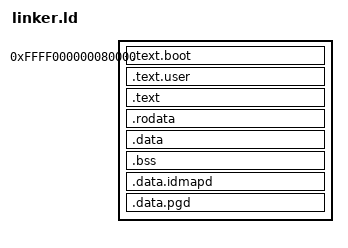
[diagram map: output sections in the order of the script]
SECTIONS
{
	. = 0xffff000000080000;
	.text.boot : { *(.text.boot) }
	. = ALIGN(0x00001000);
	user_begin = .;
	.text.user : { *(.text.user) }
	user_end = .;
	.text :  { *(.text) }
	.rodata : { *(.rodata) }
	.data : { *(.data) }
	. = ALIGN(0x8);
	bss_begin = .;
	.bss : { *(.bss*) } 
	bss_end = .;
	. = ALIGN(0x00001000);
	idmap_dir = .;
	.data.idmapd : {. += (4 * (1 << 12));}
	. = ALIGN(0x00001000);
	pg_dir = .;
	.data.pgd : { . += (3 * (1 << 12)); }
}

